# AON_IOC register map
Vendor: Texas Instruments
Peripheral module from a debugger description file (folder CC26x4).
Registers are 32-bit, access per field, reset 0x1 unless marked. A register's access mark holds for its fields unless they carry their own. Offsets are as the file gives them; lines under a group give offsets from that group; [hi:lo] are bit positions; {n}, {i} and the like mark numbered series; 'fields as' and 'values as' point back to an identical list; <NAME> marks a mode.

## AON_IOC — Always On (AON) IO Controller - controls IO operation when the MCU IO Controller (IOC) is powered off and resides in the AON domain. Note: This module only supports 32 bit Read/Write access from MCU.
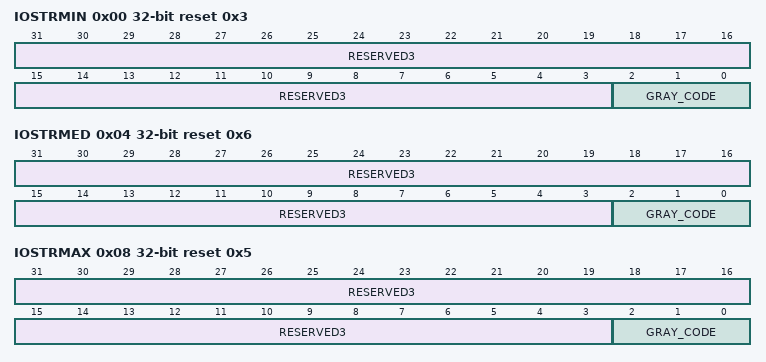
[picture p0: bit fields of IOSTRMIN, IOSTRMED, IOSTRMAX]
0x00 IOSTRMIN reset 0x3 — Internal. Only to be used through TI provided API.
  [31:3] RESERVED3 ro — Internal. Only to be used through TI provided API.
  [2:0] GRAY_CODE rw — Internal. Only to be used through TI provided API.
0x04 IOSTRMED reset 0x6 — Internal. Only to be used through TI provided API.
  fields as IOSTRMIN
0x08 IOSTRMAX reset 0x5 — Internal. Only to be used through TI provided API.
  fields as IOSTRMIN
0x0C IOCLATCH — IO Latch Control Controls transparency of all latches holding I/O or configuration state from the MCU IOC
  [0] EN rw — Controls latches between MCU IOC and AON_IOC. The latches are transparent by default. They must be closed prior to power off the domain(s) controlling the IOs in order to preserve IO values on external pins.
    1=TRANSP (Latches are transparent, meaning the value of the IO is directly controlled by the GPIO or peripheral value); 0=STATIC (Latches are static, meaning the current value on the IO pin is frozen by latches and kept even if GPIO module or a peripheral module is turned off)
0x10 CLK32KCTL — SCLK_LF External Output Control
  [0] OE_N rw — 0: Output enable active. SCLK_LF output on IO pin that has PORT_ID (for example IOC:IOCFG0.PORT_ID) set to AON_CLK32K. 1: Output enable not active
0x14 TCKCTL — TCK IO Pin Control
  [0] EN rw — 0: Input driver for TCK disabled. 1: Input driver for TCK enabled.
